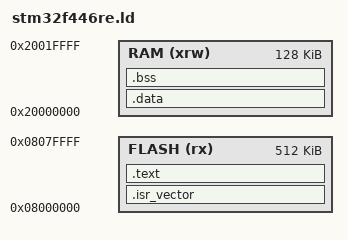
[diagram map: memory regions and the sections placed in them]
/* Very minimal linker script for STM32F446RE (512K Flash, 128K RAM) */

MEMORY
{
  FLASH (rx)  : ORIGIN = 0x08000000, LENGTH = 512K
  RAM   (xrw) : ORIGIN = 0x20000000, LENGTH = 128K
}

ENTRY(Reset_Handler)

SECTIONS
{
  .isr_vector :
  {
    . = ALIGN(4);
    KEEP(*(.isr_vector))
    . = ALIGN(4);
  } > FLASH

  .text :
  {
    . = ALIGN(4);
    *(.text*)
    *(.rodata*)
    . = ALIGN(4);
  } > FLASH

  _sidata = LOADADDR(.data);

  .data : AT (ADDR(.text) + SIZEOF(.text))
  {
    . = ALIGN(4);
    _sdata = .;
    *(.data*)
    . = ALIGN(4);
    _edata = .;
  } > RAM

  .bss :
  {
    . = ALIGN(4);
    _sbss = .;
    *(.bss*)
    *(COMMON)
    . = ALIGN(4);
    _ebss = .;
  } > RAM

  _estack = ORIGIN(RAM) + LENGTH(RAM);
}
